# MK10D5 register map
Vendor: Freescale Semiconductor, Inc.; File version: 1.6
CPU: CM4 r0p1, little endian, no MPU, no FPU, 0x4 interrupt priority bits, 0x0 interrupts
Registers are 32-bit, read-write, reset 0x0 unless marked. A register's access mark holds for its fields unless they carry their own. Offsets are from the block's base; [hi:lo] are bit positions; {n}, {i} and the like mark numbered series; 'fields as' and 'values as' point back to an identical list.

## TSI0 — Touch Sensing Input
Base 0x40045000; register names take the prefix TSI0_
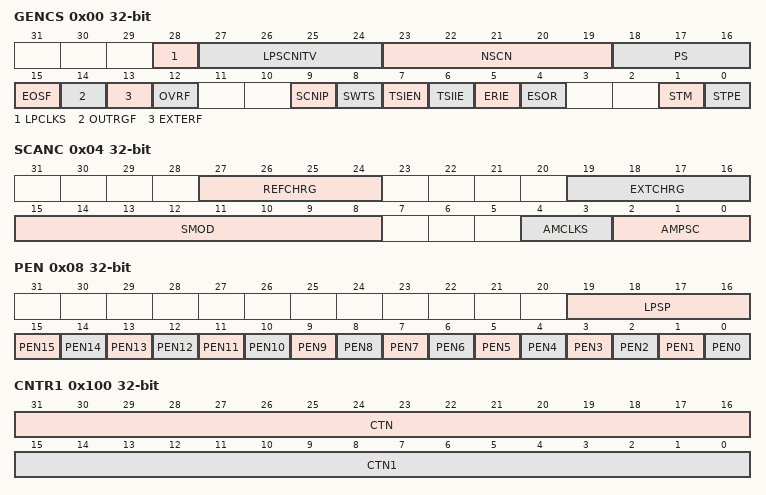
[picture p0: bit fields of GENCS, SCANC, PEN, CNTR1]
0x00 GENCS — General Control and Status Register
  [28] LPCLKS — Low Power Mode Clock Source Selection.
    0=LPOCLK is selected to determine the scan period in low power mode; 1=VLPOSCCLK is selected to determine the scan period in low power mode
  [27:24] LPSCNITV — TSI Low Power Mode Scan Interval.
    0=1 ms scan interval; 1=5 ms scan interval; 2=10 ms scan interval; 3=15 ms scan interval; 4=20 ms scan interval; 5=30 ms scan interval; 6=40 ms scan interval; 7=50 ms scan interval; 8=75 ms scan interval; 9=100 ms scan interval; 10=125 ms scan interval; 11=150 ms scan interval; 12=200 ms scan interval; 13=300 ms scan interval; 14=400 ms scan interval; 15=500 ms scan interval
  [23:19] NSCN — Number of Consecutive Scans per Electrode electrode.
    0=Once per electrode; 1=Twice per electrode; {v}={v+1} times per electrode (v=2..31)
  [18:16] PS — Electrode Oscillator prescaler. .
    0=Electrode Oscillator Frequency divided by 1; 1=Electrode Oscillator Frequency divided by 2; 2=Electrode Oscillator Frequency divided by 4; 3=Electrode Oscillator Frequency divided by 8; 4=Electrode Oscillator Frequency divided by 16; 5=Electrode Oscillator Frequency divided by 32; 6=Electrode Oscillator Frequency divided by 64; 7=Electrode Oscillator Frequency divided by 128
  [15] EOSF — End of Scan Flag.
  [14] OUTRGF — Out of Range Flag.
  [13] EXTERF — External Electrode error occurred
    0=No fault happend on TSI electrodes; 1=Short to VDD or VSS was detected on one or more electrodes
  [12] OVRF — Overrun error Flag. This flag is set when a scan trigger occurs while a scan is still in progress. Write "1", when this flag is set, to clear it..
    0=No over run; 1=Over Run occurred
  [9] SCNIP ro — Scan In Progress status
  [8] SWTS wo — Software Trigger Start
  [7] TSIEN — Touch Sensing Input Module Enable
    0=TSI module is disabled; 1=TSI module is enabled
  [6] TSIIE — Touch Sensing Input Interrupt Module Enable
    0=Interrupt from TSI is disabled; 1=Interrupt from TSI is enabled
  [5] ERIE — Error Interrupt Enable
    0=Interrupt disabled for error; 1=Interrupt enabled for error
  [4] ESOR — End-of-Scan or Out-of-Range Interrupt select
    0=Out-of-Range interrupt is allowed; 1=End-of-Scan interrupt is allowed
  [1] STM — Scan Trigger Mode. This bit-field can only be changed if the TSI module is disabled (TSIEN bit = 0).
    0=Software trigger scan; 1=Periodical Scan
  [0] STPE
    0=Disable TSI when MCU goes into low power modes; 1=Allows TSI to continue running in all low power modes
0x04 SCANC — SCAN Control Register
  [27:24] REFCHRG — Ref OSC Charge Current select
    0=2 uA charge current; 1=4 uA charge current; 2=6 uA charge current; 3=8 uA charge current; 4=10 uA charge current; 5=12 uA charge current; 6=14 uA charge current; 7=16 uA charge current; 8=18 uA charge current; 9=20 uA charge current; 10=22 uA charge current; 11=24 uA charge current; 12=26 uA charge current; 13=28 uA charge current; 14=30 uA charge current; 15=32 uA charge current
  [19:16] EXTCHRG — External OSC Charge Current select
    values as REFCHRG
  [15:8] SMOD — Scan Module
    0=Continue Scan
  [4:3] AMCLKS — Active Mode Clock Source
    0=LPOSCCLK; 1=MCGIRCLK; 2=OSCERCLK; 3=Not valid
  [2:0] AMPSC — Active Mode Prescaler
    0=Input Clock Source divided by 1; 1=Input Clock Source divided by 2; 2=Input Clock Source divided by 4; 3=Input Clock Source divided by 8; 4=Input Clock Source divided by 16; 5=Input Clock Source divided by 32; 6=Input Clock Source divided by 64; 7=Input Clock Source divided by 128
0x08 PEN — Pin Enable Register
  [19:16] LPSP — Low Power Scan Pin
    {v}=TSI_IN[{v}] is active in low power mode (v=0..15)
  [n] PEN{n} (n=0..15) — Touch Sensing Input Pin Enable Register {n}
    0=The corresponding pin is not used by TSI; 1=The corresponding pin is used by TSI
0x0C WUCNTR ro — Wake-Up Channel Counter Register
  [15:0] WUCNT — TouchSensing wake-up Channel 16bit counter value
0x100 CNTR1 ro — Counter Register
  [31:16] CTN — TouchSensing Channel n 16-bit counter value
  [15:0] CTN1 — TouchSensing Channel n-1 16-bit counter value
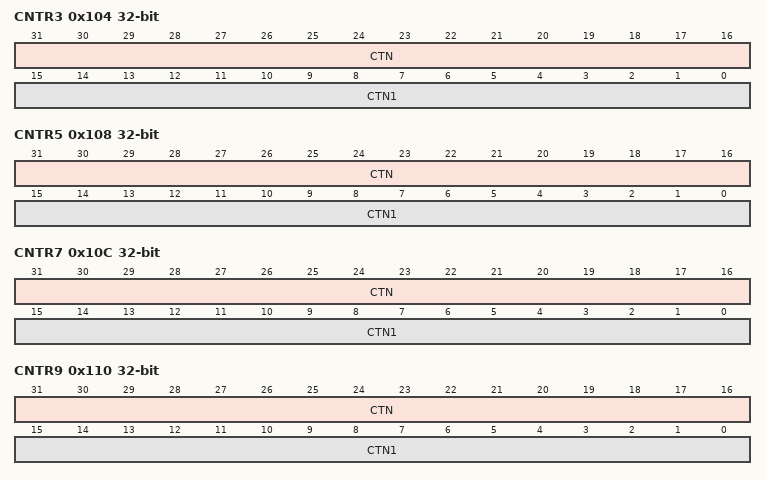
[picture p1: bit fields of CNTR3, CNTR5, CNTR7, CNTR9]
0x104 CNTR3 ro — Counter Register
  fields as CNTR1
0x108 CNTR5 ro — Counter Register
  fields as CNTR1
0x10C CNTR7 ro — Counter Register
  fields as CNTR1
0x110 CNTR9 ro — Counter Register
  fields as CNTR1
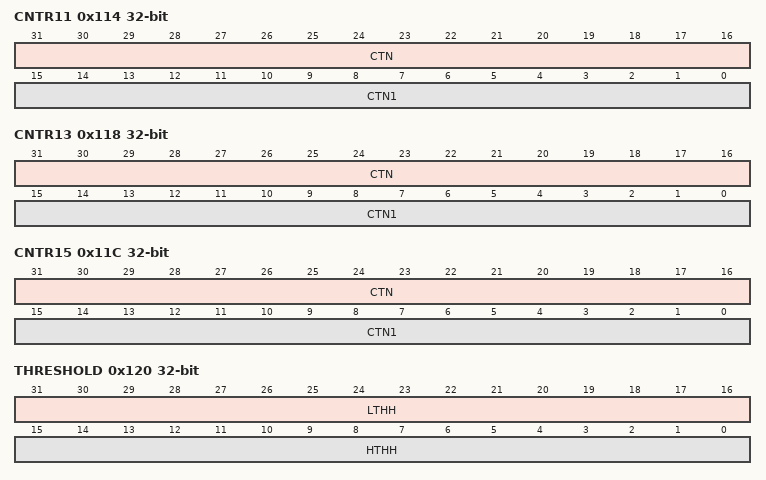
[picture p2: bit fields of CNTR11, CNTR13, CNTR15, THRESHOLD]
0x114 CNTR11 ro — Counter Register
  fields as CNTR1
0x118 CNTR13 ro — Counter Register
  fields as CNTR1
0x11C CNTR15 ro — Counter Register
  fields as CNTR1
0x120 THRESHOLD — Low Power Channel Threshold Register
  [31:16] LTHH — Touch Sensing Channel Low Threshold value
  [15:0] HTHH — Touch Sensing Channel High Threshold value
